# STM32H533 register map
File version: 1.3
CPU: CM33 r0p0, little endian, MPU, FPU, 4 interrupt priority bits
Registers are 32-bit, read-write, reset 0x0 unless marked. A register's access mark holds for its fields unless they carry their own. Offsets are from the block's base; [hi:lo] are bit positions; {n}, {i} and the like mark numbered series; 'fields as' and 'values as' point back to an identical list.

## PWR — PWR address block description
Base 0x44020800
Same registers: PWR_S 0x54020800
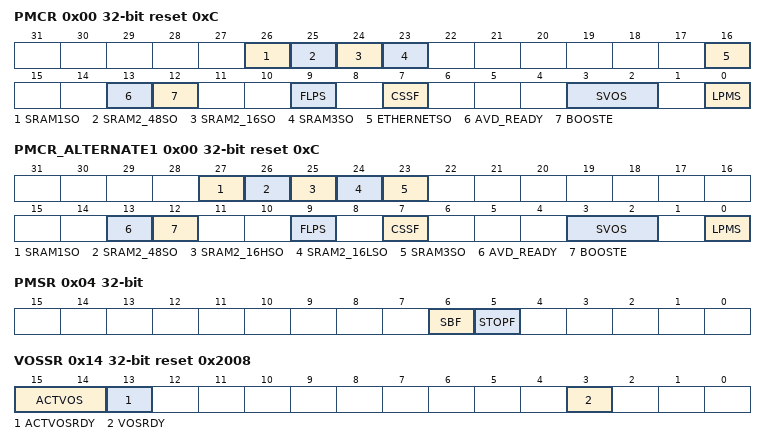
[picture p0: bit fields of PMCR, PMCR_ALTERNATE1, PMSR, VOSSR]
0x00 PMCR reset 0xC — PWR power mode control register
  [26] SRAM1SO — AHB SRAM1 shut-off in Stop mode
    0=Kept (AHB RAM1 content is kept in Stop mode); 1=Lost (AHB RAM1 content is lost in Stop mode)
  [25] SRAM2_48SO — AHB SRAM2 48-Kbyte shut-off in Stop mode.
    0=Kept (AHB RAM2 content is kept in Stop mode); 1=Lost (AHB RAM2 content is lost in Stop mode)
  [24] SRAM2_16SO — AHB SRAM2 16-Kbyte shut-off in Stop mode.
    values as SRAM2_48SO
  [23] SRAM3SO — AHB SRAM3 shut-off in Stop mode.
  [16] ETHERNETSO — ETHERNET RAM shut-off in Stop mode.
  [13] AVD_READY — analog voltage ready
    0=NotReady (Peripheral analog voltage VDDA not ready (default)); 1=Ready (Peripheral analog voltage VDDA ready)
  [12] BOOSTE — analog switch Vless thansub>BOOSTless than/sub> control
    0=Disabled (Booster disabled); 1=Enabled (Booster enabled if analog voltage ready (AVD_READY = 1))
  [9] FLPS — flash memory low-power mode in Stop mode
    0=NormalMode (Flash memory remains in normal mode when the system enters Stop mode); 1=LowPowerMode (Flash memory enters low-power mode when the system enters Stop mode)
  [7] CSSF — clear Standby and Stop flags (always read as 0)
    1=Clear (STOPF and SBF flags cleared)
  [3:2] SVOS — system Stop mode voltage scaling selection
    1=Scale5 (SVOS5 scale 5); 2=Scale4 (SVOS4 scale 4); 3=Scale3 (SVOS3 scale 3)
  [0] LPMS — low-power mode selection
    0=StopMode (Keeps Stop mode when entering DeepSleep); 1=StandbyMode (Allows Standby mode when entering DeepSleep)
0x00 PMCR_ALTERNATE1 reset 0xC (alternate view of PMCR) — PWR power mode control register
  [27] SRAM1SO — AHB SRAM1 shut-off in Stop mode
  [26] SRAM2_48SO — AHB SRAM2 48-Kbyte shut-off in Stop mode.
  [25] SRAM2_16HSO — AHB SRAM2 high 16-Kbyte shut-off in Stop mode.
  [24] SRAM2_16LSO — AHB SRAM2 low 16-Kbyte shut-off in Stop mode.
  [23] SRAM3SO — AHB SRAM3 shut-off in Stop mode.
  [13] AVD_READY — analog voltage ready
  [12] BOOSTE — analog switch Vless thansub>BOOSTless than/sub> control
  [9] FLPS — flash memory low-power mode in Stop mode
  [7] CSSF — clear Standby and Stop flags (always read as 0)
  [3:2] SVOS — system Stop mode voltage scaling selection
  [0] LPMS — low-power mode selection
0x04 PMSR ro — PWR status register
  [6] SBF — System standby flag
    0=NoStandbyMode (System has not been in standby mode); 1=StandbyModePreviouslyEntered (System has been in Standby mode)
  [5] STOPF — Stop flag
    0=NoStopMode (System has not been in stop mode); 1=StopModePreviouslyEntered (System has been in Stop mode)
0x10 VOSCR — PWR voltage scaling control register
  [5:4] VOS — voltage scaling selection according to performance
    0=Scale 3 (default); 1=Scale 1; 2=Scale 2; 3=Scale 0
0x14 VOSSR ro reset 0x2008 — PWR voltage scaling status register
  [15:14] ACTVOS — voltage output scaling currently applied to Vless thansub>COREless than/sub>
    0=VOS3 (VOS3 (lowest power)); 1=VOS2; 2=VOS1; 3=VOS0 (VOS0 (highest frequency))
  [13] ACTVOSRDY — Voltage level ready for currently used VOS
    0=NotReady (VCORE is above or below the current voltage scaling provided by ACTVOS[1:0]); 1=Ready (VCORE is equal to the current voltage scaling provided by ACTVOS[1:0])
  [3] VOSRDY — Ready bit for Vless thansub>COREless than/sub> voltage scaling output selection.
    0=Not ready, voltage level below VOS selected level; 1=Ready, voltage level at or above VOS selected level
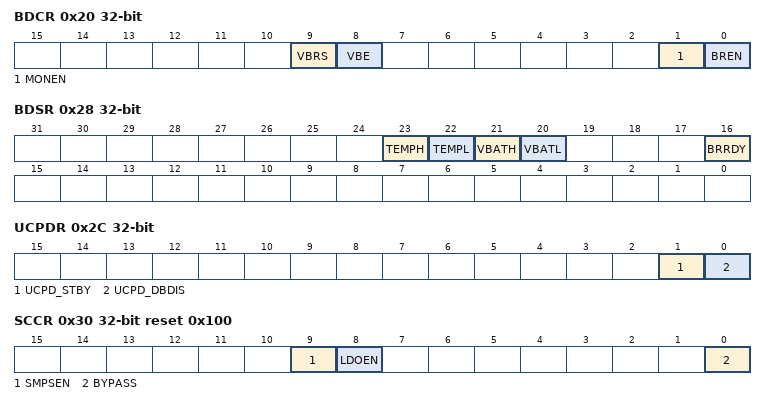
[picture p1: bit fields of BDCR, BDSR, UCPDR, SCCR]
0x20 BDCR — PWR Backup domain control register
  [9] VBRS — Vless thansub>BATless than/sub> charging resistor selection
    0=Charge5k (Charge VBAT through a 5 kΩ resistor); 1=Charge1k5 (Charge VBAT through a 1.5 kΩ resistor)
  [8] VBE — Vless thansub>BATless than/sub> charging enable
    0=Disabled (VBAT battery charging disabled); 1=Enabled (VBAT battery charging enabled)
  [1] MONEN — Backup domain voltage and temperature monitoring enable
    0=Disabled (Backup domain voltage and temperature monitoring disabled); 1=Enabled (Backup domain voltage and temperature monitoring enabled)
  [0] BREN — Backup RAM retention in Standby and Vless thansub>BATless than/sub> modes
    0=Disabled (Backup regulator enabled; backup RAM content lost in Standby and VBAT modes); 1=Enabled (Backup regulator disabled; backup RAM content preserved in Standby and VBAT modes)
0x24 DBPCR — PWR Backup domain control register
  [0] DBP — Disable Backup domain write protection
    0=Disabled (Write access to backup domain disabled); 1=Enabled (Write access to backup domain enabled)
0x28 BDSR ro — PWR Backup domain status register
  [23] TEMPH — temperature level monitoring versus high threshold
    0=BelowThreshold (Below high threshold level); 1=AboveThreshold (Equal to or Above high threshold level)
  [22] TEMPL — temperature level monitoring versus low threshold
    0=AboveThreshold (Above low threshold level); 1=BelowThreshold (Equal to or below low threshold level)
  [21] VBATH — Vless thansub>BATless than/sub> level monitoring versus high threshold
    values as TEMPH
  [20] VBATL — Vless thansub>BATless than/sub> level monitoring versus low threshold
    values as TEMPL
  [16] BRRDY — backup regulator ready
    0=NotReady (Backup regulator not ready); 1=Ready (Backup regulator ready)
0x2C UCPDR — PWR USB Type-C power delivery register
  [1] UCPD_STBY — USB Type-c and Power delivery Standby mode
  [0] UCPD_DBDIS — USB Type-C and power delivery dead battery disable
0x30 SCCR rw-once reset 0x100 — PWR supply configuration control register
  [9] SMPSEN ro — SMPS enable
  [8] LDOEN ro — LDO enable
    0=Disabled (Package does not use LDO regulator); 1=Enabled (Package uses LDO regulator)
  [0] BYPASS — power management unit bypass
    0=InternalRegulator (Power management unit normal operation. Use the internal regulator.); 1=Bypassed (Power management unit bypassed. Use the external power.)
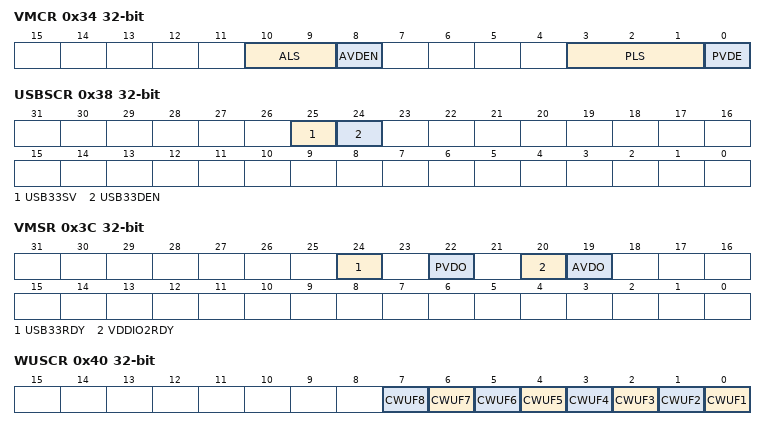
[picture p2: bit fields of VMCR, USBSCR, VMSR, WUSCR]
0x34 VMCR — PWR voltage monitor control register
  [10:9] ALS — analog voltage detector (AVD) level selection
    0=AVD level0 (VAVD0 around 1.7 V); 1=AVD level1 (VAVD1 around 2.1 V); 2=AVD level2 (VAVD2 around 2.5 V); 3=AVD level3 (VAVD3 around 2.8 V)
  [8] AVDEN — peripheral voltage monitor on Vless thansub>DDAless than/sub> enable
    0=Disabled (Peripheral voltage monitor on VDDA disabled); 1=Enabled (Peripheral voltage monitor on VDDA enabled)
  [3:1] PLS — programmable voltage detector (PVD) level selection
    0=PVD level0 (VPVD0 around 1.95 V); 1=PVD level1 (VPVD1 around 2.1 V); 2=PVD level2 (VPVD2 around 2.25 V); 3=PVD level3 (VPVD3 around 2.4 V); 4=PVD level4 (VPVD4 around 2.55 V); 5=PVD level5 (VPVD5 around 2.7 V); 6=PVD level6 (VPVD6 around 2.85 V); 7=PVD_IN pin
  [0] PVDE — PVD enable
    0=Disabled (PVD Disabled); 1=Enabled (PVD Enabled)
0x38 USBSCR — PWR USB supply control register
  [25] USB33SV — independent USB supply valid
  [24] USB33DEN — Vless thansub>DDUSBless than/sub> voltage level detector enable
0x3C VMSR ro (reset mask 0xFF0FFFFF) — PWR voltage monitor status register
  [24] USB33RDY — Vless thansub>DDUSBless than/sub> ready
  [22] PVDO — programmable voltage detect output
    0=AboveThreshold (VDD is equal or higher than the PVD threshold selected through the PLS[2:0] bits.); 1=BelowThreshold (VDD is lower than the PVD threshold selected through the PLS[2:0] bits)
  [20] VDDIO2RDY — voltage detector output on Vless thansub>DDIO2less than/sub>
    0=BelowThreshold (VDDIO2 is below the threshold of the VDDIO2 voltage monitor); 1=AboveThreshold (VDDIO2 is equal or above the threshold of the VDDIO2 voltage monitor)
  [19] AVDO — analog voltage detector output on Vless thansub>DDAless than/sub>
    0=AboveThreshold (VDDA is equal or higher than the AVD threshold selected with the ALS[2:0] bits); 1=BelowThreshold (VDDA is lower than the AVD threshold selected with the ALS[2:0] bits)
0x40 WUSCR wo — PWR wake-up status clear register
  [all] fields
    1=Clear (Writing 1 clears the WUFx wakeup pin flag (bit is cleared to 0 by hardware))
  [n-1] CWUF{n} (n=1..8) — clear wake-up pin flag for WUFx (x = 8 to 1)
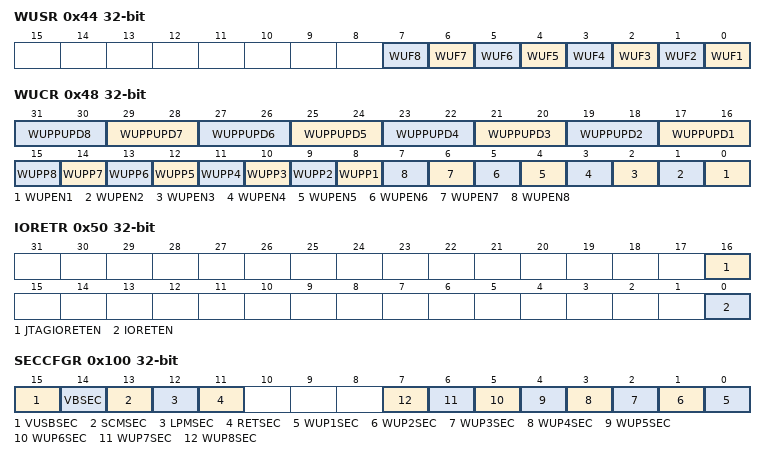
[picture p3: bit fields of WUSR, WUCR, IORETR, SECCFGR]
0x44 WUSR ro — PWR wake-up status register
  [all] fields
    0=NoEventOccurred (No wakeup event occurred); 1=EventOccurred (A wakeup event received from WUFx pin)
  [n-1] WUF{n} (n=1..8) — wake-up pin WUFx flag
0x48 WUCR — PWR wake-up configuration register
  [2n+15:2n+14] WUPPUPD{n} (n=1..8) — wake-up pin pull configuration for WKUPx (x = 8 to 1)
    0=No pull-up or pull-down; 1=PullUp; 2=PullDown
  [n+7] WUPP{n} (n=1..8) — wake-up pin polarity bit for WUPx (x = 8 to 1)
    0=HighLevel (Detection on high level); 1=LowLevel (Detection on low level)
  [n-1] WUPEN{n} (n=1..8) — enable wake-up pin WUPx (x = 8 to 1)
    0=Disabled (An event on WUPx pin does not wakeup the system from Standby mode); 1=Enabled (A rising or falling edge on WUPx pin wakes up the system from Standby mode)
0x50 IORETR — PWR I/O retention register
  [16] JTAGIORETEN — IO retention enable for JTAG IOs
    0=Disabled (IO Retention mode is disabled); 1=Enabled (IO Retention mode is enabled)
  [0] IORETEN — IO retention enable
    values as JTAGIORETEN
0x100 SECCFGR — PWR security configuration register
  [15] VUSBSEC — voltage USB secure protection
  [14] VBSEC — Backup domain secure protection
  [13] SCMSEC — supply configuration and monitoring secure protection.
  [12] LPMSEC — low-power modes secure protection
  [11] RETSEC — retention secure protection
  [n-1] WUP{n}SEC (n=1..8) — WUPx secure protection (x = 8 to 1)
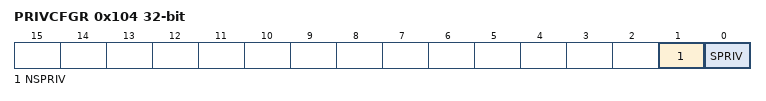
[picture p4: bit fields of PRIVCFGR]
0x104 PRIVCFGR — PWR privilege configuration register
  [1] NSPRIV — PWR non-secure functions privilege configuration
    0=Unprivileged (Read and write to PWR functions can be done by privileged or unprivileged access); 1=Privileged (Read and write to PWR functions can be done by privileged access only)
  [0] SPRIV — PWR secure functions privilege configuration
